# nrf54lm20a_enga_application register map
Vendor: Nordic Semiconductor; Series: nrf54l; File version: 1
CPU: CM33 r0p4, little endian, MPU, FPU, 3 interrupt priority bits, 270 interrupts, 4 SAU regions
Registers are 32-bit, read-write, reset 0x0 unless marked. A register's access mark holds for its fields unless they carry their own. Offsets are from the block's base; [hi:lo] are bit positions; {n}, {i} and the like mark numbered series; 'fields as' and 'values as' point back to an identical list.

## ETM_NS — Embedded Trace Macrocell
Base 0xE0041000
0x04 TRCPRGCTLR — Enables the trace unit.
  [0] EN — Trace unit enable bit
    0=Disabled (The trace unit is disabled. All trace resources are inactive and no trace is generated.); 1=Enabled (The trace unit is enabled.)
0x08 TRCPROCSELR — Controls which PE to trace. Might ignore writes when the trace unit is enabled or not idle. Before writing to this register, ensure that TRCSTATR.IDLE == 1 so that the trace unit can synchronize with the chosen PE. Implemented if TRCIDR3.NUMPROC is greater than zero.
  [4:0] PROCSEL — PE select bits that select the PE to trace.
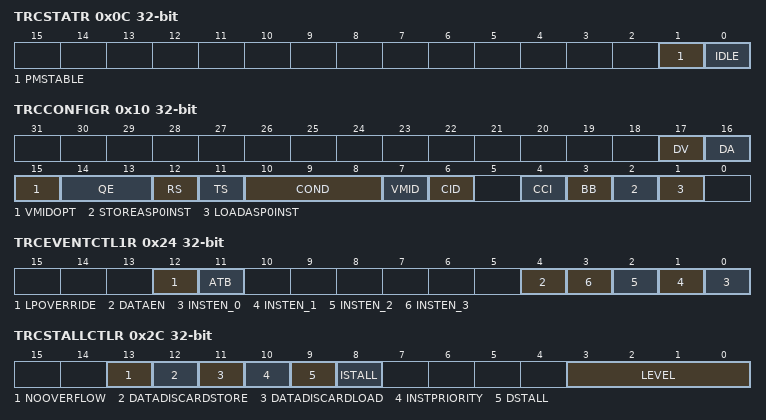
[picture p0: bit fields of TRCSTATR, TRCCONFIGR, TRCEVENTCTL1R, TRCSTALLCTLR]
0x0C TRCSTATR — Idle status bit
  [1] PMSTABLE — Programmers' model stable bit
    0=NotStable (The programmers' model is not stable.); 1=Stable (The programmers' model is stable.)
  [0] IDLE — Trace unit enable bit
    0=NotIdle (The trace unit is not idle.); 1=Idle (The trace unit is idle.)
0x10 TRCCONFIGR — Controls the tracing options This register must always be programmed as part of trace unit initialization. Might ignore writes when the trace unit is enabled or not idle.
  [17] DV — Data value tracing bit.
    0=Disabled (Data value tracing is disabled.); 1=Enabled (Data value tracing is enabled.)
  [16] DA — Data address tracing bit.
    0=Disabled (Data address tracing is disabled.); 1=Enabled (Data address tracing is enabled.)
  [15] VMIDOPT — Control bit to select the Virtual context identifier value used by the trace unit, both for trace generation and in the Virtual context identifier comparators.
    0=VTTBR_EL2 (VTTBR_EL2.VMID is used. If the trace unit supports a Virtual context identifier larger than the VTTBR_EL2.VMID, the upper unused bits are always zero. If the trace unit supports a Virtual context identifier larger than 8 bits and if the VTCR_EL2.VS bit forces use of an 8-bit Virtual context identifier, bits [15:8] of the trace unit Virtual context identifier are always zero.); 1=CONTEXTIDR_EL2 (CONTEXTIDR_EL2 is used.)
  [14:13] QE — Q element enable field.
    0=Disabled (Q elements are disabled.); 1=OnlyWithoutInstCounts (Q elements with instruction counts are enabled. Q elements without instruction counts are disabled.); 3=Enabled (Q elements with and without instruction counts are enabled.)
  [12] RS — Return stack enable bit.
    0=Disabled (Return stack is disabled.); 1=Enabled (Return stack is enabled.)
  [11] TS — Global timestamp tracing bit.
    0=Disabled (Global timestamp tracing is disabled.); 1=Enabled (Global timestamp tracing is enabled.)
  [10:8] COND — Conditional instruction tracing bit.
    0=Disabled (Conditional instruction tracing is disabled.); 1=LoadOnly (Conditional load instructions are traced.); 2=StoreOnly (Conditional store instructions are traced.); 3=LoadAndStore (Conditional load and store instructions are traced.); 7=All (All conditional instructions are traced.)
  [7] VMID — Virtual context identifier tracing bit.
    0=Disabled (Virtual context identifier tracing is disabled.); 1=Enabled (Virtual context identifier tracing is enabled.)
  [6] CID — Context ID tracing bit.
    0=Disabled (Context ID tracing is disabled.); 1=Enabled (Context ID tracing is enabled.)
  [4] CCI — Cycle counting instruction trace bit.
    0=Disabled (Cycle counting in the instruction trace is disabled.); 1=Enabled (Cycle counting in the instruction trace is enabled.)
  [3] BB — Branch broadcast mode bit.
    0=Disabled (Branch broadcast mode is disabled.); 1=Enabled (Branch broadcast mode is enabled.)
  [2] STOREASP0INST — Instruction P0 field. This field controls whether store instructions are traced as P0 instructions.
    0=No (Do not trace store instructions as P0 instructions.); 1=Yes (Trace store instructions as P0 instructions.)
  [1] LOADASP0INST — Instruction P0 load field. This field controls whether load instructions are traced as P0 instructions.
    0=No (Do not trace load instructions as P0 instructions.); 1=Yes (Trace load instructions as P0 instructions.)
0x20 TRCEVENTCTL0R — Controls the tracing of arbitrary events. If the selected event occurs a trace element is generated in the trace stream according to the settings in TRCEVENTCTL1R.DATAEN and TRCEVENTCTL1R.INSTEN.
  [7:0] EVENT — Select which event should generate trace elements.
0x24 TRCEVENTCTL1R — Controls the behavior of the events that TRCEVENTCTL0R selects. This register must always be programmed as part of trace unit initialization. Might ignore writes when the trace unit is enabled or not idle.
  [12] LPOVERRIDE — Low-power state behavior override bit. Controls how a trace unit behaves in low-power state.
    0=Disabled (Trace unit low-power state behavior is not affected. That is, the trace unit is enabled to enter low-power state.); 1=Enabled (Trace unit low-power state behavior is overridden. That is, entry to a low-power state does not affect the trace unit resources or trace generation.)
  [11] ATB — AMBA Trace Bus (ATB) trigger enable bit.
    0=Disabled (ATB trigger is disabled.); 1=Enabled (ATB trigger is enabled. If a CoreSight ATB interface is implemented then when event 0 occurs the trace unit generates an ATB event.)
  [4] DATAEN — Data event enable bit.
    0=Disabled (The trace unit does not generate an Event element if event 0 occurs.); 1=Enabled (The trace unit generates an Event element in the data trace stream if event 0 occurs.)
  [n] INSTEN_{n} (n=0..3) — Instruction event enable field.
    0=Disabled (The trace unit does not generate an Event element.); 1=Enabled (The trace unit generates an Event element for event {n}, in the instruction trace stream.)
0x2C TRCSTALLCTLR — Enables trace unit functionality that prevents trace unit buffer overflows. Might ignore writes when the trace unit is enabled or not idle. Must be programmed if TRCIDR3.STALLCTL == 1.
  [13] NOOVERFLOW — Trace overflow prevention bit.
    0=Disabled (Trace overflow prevention is disabled.); 1=Enabled (Trace overflow prevention is enabled. This might cause a significant performance impact.)
  [12] DATADISCARDSTORE — Data discard field. Controls if a trace unit can discard data trace elements on a store when the data trace buffer space is less than LEVEL.
    0=Disabled (The trace unit must not discard any data trace elements.); 1=Enabled (The trace unit can discard P1 and P2 elements associated with data stores.)
  [11] DATADISCARDLOAD — Data discard field. Controls if a trace unit can discard data trace elements on a load when the data trace buffer space is less than LEVEL.
    0=Disabled (The trace unit must not discard any data trace elements.); 1=Enabled (The trace unit can discard P1 and P2 elements associated with data loads.)
  [10] INSTPRIORITY — Prioritize instruction trace bit. Controls if a trace unit can prioritize instruction trace when the instruction trace buffer space is less than LEVEL.
    0=Disabled (The trace unit must not prioritize instruction trace.); 1=Enabled (The trace unit can prioritize instruction trace. A trace unit might prioritize instruction trace by preventing output of data trace, or other means which ensure that the instruction trace has a higher priority than the data trace.)
  [9] DSTALL — Data stall bit. Controls if a trace unit can stall the PE when the data trace buffer space is less than LEVEL.
    0=Disabled (The trace unit must not stall the PE.); 1=Enabled (The trace unit can stall the PE.)
  [8] ISTALL — Instruction stall bit. Controls if a trace unit can stall the PE when the instruction trace buffer space is less than LEVEL.
    values as DSTALL
  [3:0] LEVEL — Threshold level field. If LEVEL is nonzero then a trace unit might suppress the generation of: Global timestamps in the instruction trace stream and the data trace stream. Cycle counting in the instruction trace stream, although the cumulative cycle count remains correct.
    0=Min (Zero invasion. This setting has a greater risk of a FIFO overflow); 15=Max (Maximum invasion occurs but there is less risk of a FIFO overflow.)
0x30 TRCTSCTLR — Controls the insertion of global timestamps in the trace streams. When the selected event is triggered, the trace unit inserts a global timestamp into the trace streams. Might ignore writes when the trace unit is enabled or not idle. Must be programmed if TRCCONFIGR.TS == 1.
  [7:0] EVENT — Select which event should generate time stamps.
0x34 TRCSYNCPR — Controls how often trace synchronization requests occur. Might ignore writes when the trace unit is enabled or not idle. If writes are permitted then the register must be programmed.
  [4:0] PERIOD — Controls how many bytes of trace, the sum of instruction and data, that a trace unit can generate before a trace synchronization request occurs. The number of bytes is always a power of two, calculated by 2^PERIOD
    0=Disabled (Trace synchronization requests are disabled. This setting does not disable other types of trace synchronization request.)
0x38 TRCCCCTLR — Sets the threshold value for cycle counting. Might ignore writes when the trace unit is enabled or not idle. Must be programmed if TRCCONFIGR.CCI==1.
  [11:0] THRESHOLD — Sets the threshold value for instruction trace cycle counting.
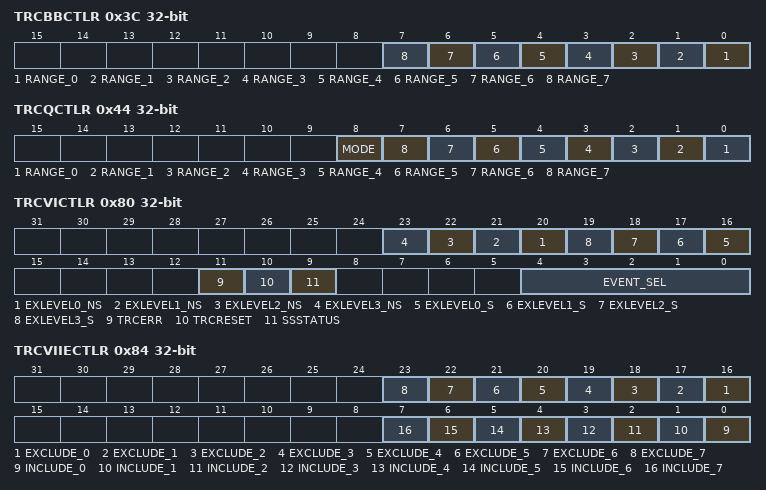
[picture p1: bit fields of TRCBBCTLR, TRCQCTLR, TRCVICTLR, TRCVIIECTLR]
0x3C TRCBBCTLR — Controls which regions in the memory map are enabled to use branch broadcasting. Might ignore writes when the trace unit is enabled or not idle. Must be programmed if TRCCONFIGR.BB == 1.
  [n] RANGE_{n} (n=0..7) — Address range field. Selects which address range comparator pairs are in use with branch broadcasting. Each field represents an address range comparator pair, so field[{n}] controls the selection of address range comparator pair {n}.
    0=Disabled (The address range that address range comparator pair {n} defines, is not selected.); 1=Enabled (The address range that address range comparator pair n defines, is selected.)
0x40 TRCTRACEIDR — Sets the trace ID for instruction trace. If data trace is enabled then it also sets the trace ID for data trace, to (trace ID for instruction trace) + 1. This register must always be programmed as part of trace unit initialization. Might ignore writes when the trace unit is enabled or not idle.
  [6:0] TRACEID — Trace ID field. Sets the trace ID value for instruction trace. Bit[0] must be zero if data trace is enabled. If data trace is enabled then a trace unit sets the trace ID for data trace, to TRACEID+1.
0x44 TRCQCTLR — Controls when Q elements are enabled. Might ignore writes when the trace unit is enabled or not idle. This register must be programmed if it is implemented and TRCCONFIGR.QE is set to any value other than 0b00.
  [8] MODE — Selects whether the address range comparators selected by the RANGE field indicate address ranges where the trace unit is permitted to generate Q elements or address ranges where the trace unit is not permitted to generate Q elements:
    0=Exclude mode. The address range comparators selected by the RANGE field indicate address ranges where the trace unit cannot generate Q elements. If no ranges are selected, Q elements are permitted across the entire memory map.; 1=Include mode. The address range comparators selected by the RANGE field indicate address ranges where the trace unit can generate Q elements. If all the implemented bits in RANGE are set to 0 then Q elements are disabled.
  [n] RANGE_{n} (n=0..7) — Specifies the address range comparators to be used for controlling Q elements.
    0=Disabled (Address range comparator {n} is disabled.); 1=Enabled (Address range comparator {n} is selected for use.)
0x80 TRCVICTLR — Controls instruction trace filtering. Might ignore writes when the trace unit is enabled or not idle. Only returns stable data when TRCSTATR.PMSTABLE == 1. Must be programmed, particularly to set the value of the SSSTATUS bit, which sets the state of the start/stop logic.
  [n+20] EXLEVEL{n}_NS (n=0..3) — In Non-secure state, each bit controls whether instruction tracing is enabled for the corresponding Exception level {n}.
    1=Disabled (The trace unit does not generate instruction trace, in Non-secure state, for Exception level {n}.); 0=Enabled (The trace unit generates instruction trace, in Non-secure state, for Exception level {n}.)
  [n+16] EXLEVEL{n}_S (n=0..3) — In Secure state, each bit controls whether instruction tracing is enabled for the corresponding Exception level {n}.
    1=Disabled (The trace unit does not generate instruction trace, in Secure state, for Exception level {n}.); 0=Enabled (The trace unit generates instruction trace, in Secure state, for Exception level {n}.)
  [11] TRCERR — When TRCIDR3.TRCERR==1, this bit controls whether a trace unit must trace a System error exception.
    0=Disabled (The trace unit does not trace a System error exception unless it traces the exception or instruction immediately prior to the System error exception.); 1=Enabled (The trace unit always traces a System error exception, regardless of the value of ViewInst.)
  [10] TRCRESET — Controls whether a trace unit must trace a Reset exception.
    0=Disabled (The trace unit does not trace a Reset exception unless it traces the exception or instruction immediately prior to the Reset exception.); 1=Enabled (The trace unit always traces a Reset exception.)
  [9] SSSTATUS — When TRCIDR4.NUMACPAIRS > 0 or TRCIDR4.NUMPC > 0, this bit returns the status of the start/stop logic.
    0=Stopped (The start/stop logic is in the stopped state.); 1=Started (The start/stop logic is in the started state.)
  [4:0] EVENT_SEL — Select which resource number should be filtered.
    0=Disabled (This event is not filtered.); 1=Enabled (This event is filtered.)
0x84 TRCVIIECTLR — ViewInst exclude control. Might ignore writes when the trace unit is enabled or not idle. This register must be programmed when one or more address comparators are implemented.
  [n+16] EXCLUDE_{n} (n=0..7) — Exclude range field. Selects which address range comparator pairs are in use with ViewInst exclude control.
    0=Disabled (The address range that address range comparator pair {n} defines, is not selected for ViewInst exclude control.); 1=Enabled (The address range that address range comparator pair {n} defines, is selected for ViewInst exclude control.)
  [n] INCLUDE_{n} (n=0..7) — Include range field. Selects which address range comparator pairs are in use with ViewInst include control.
    0=Disabled (The address range that address range comparator pair {n} defines, is not selected for ViewInst include control.); 1=Enabled (The address range that address range comparator pair {n} defines, is selected for ViewInst include control.)
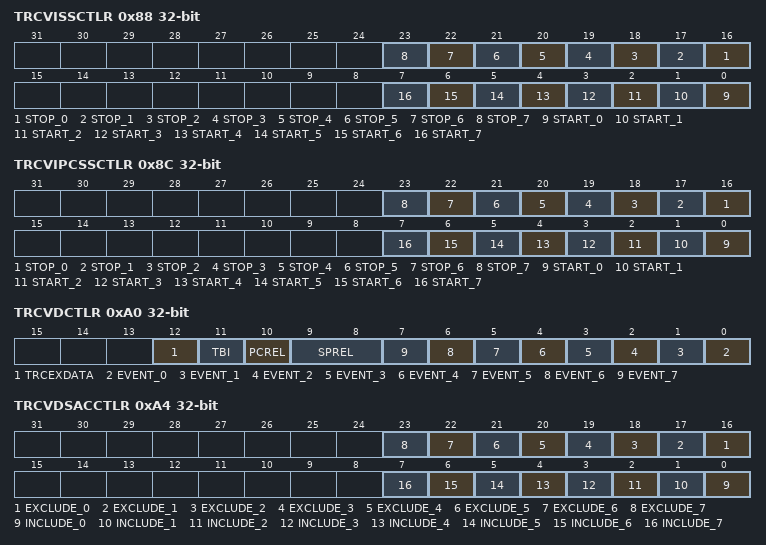
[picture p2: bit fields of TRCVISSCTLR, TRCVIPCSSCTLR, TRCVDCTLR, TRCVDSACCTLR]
0x88 TRCVISSCTLR — Use this to set, or read, the single address comparators that control the ViewInst start/stop logic. The start/stop logic is active for an instruction which causes a start and remains active up to and including an instruction which causes a stop, and then the start/stop logic becomes inactive. Might ignore writes when the trace unit is enabled or not idle. If implemented then this register must be programmed.
  [n+16] STOP_{n} (n=0..7) — Selects which single address comparators are in use with ViewInst start/stop control, for the purpose of stopping trace
    0=Disabled (The single address comparator {n}, is not selected as a stop resource.); 1=Enabled (The single address comparator {n}, is selected as a stop resource.)
  [n] START_{n} (n=0..7) — Selects which single address comparators are in use with ViewInst start/stop control, for the purpose of starting trace.
    0=Disabled (The single address comparator {n}, is not selected as a start resource.); 1=Enabled (The single address comparator {n}, is selected as a start resource.)
0x8C TRCVIPCSSCTLR — Use this to set, or read, which PE comparator inputs can control the ViewInst start/stop logic. Might ignore writes when the trace unit is enabled or not idle. If implemented then this register must be programmed.
  [n+16] STOP_{n} (n=0..7) — Selects which PE comparator inputs are in use with ViewInst start/stop control, for the purpose of stopping trace.
    0=Disabled (The single PE comparator input {n}, is not selected as a stop resource.); 1=Enabled (The single PE comparator input {n}, is selected as a stop resource.)
  [n] START_{n} (n=0..7) — Selects which PE comparator inputs are in use with ViewInst start/stop control, for the purpose of starting trace
    0=Disabled (The single PE comparator input {n}, is not selected as a start resource.); 1=Enabled (The single PE comparator input {n}, is selected as a start resource.)
0xA0 TRCVDCTLR — Controls data trace filtering. Might ignore writes when the trace unit is enabled or not idle. This register must be programmed when data tracing is enabled, that is, when either TRCCONFIGR.DA == 1 or TRCCONFIGR.DV == 1.
  [12] TRCEXDATA — Controls the tracing of data transfers for exceptions and exception returns on Armv6-M, Armv7-M, and Armv8-M PEs.
    0=Disabled (Exception and exception return data transfers are not traced.); 1=Enabled (Exception and exception return data transfers are traced if the other aspects of ViewData indicate that the data transfers must be traced.)
  [11] TBI — Controls which information a trace unit populates in bits[63:56] of the data address.
    0=SignExtend (The trace unit assigns bits[63:56] to have the same value as bit[55] of the data address, that is, it sign-extends the value.); 1=Copy (The trace unit assigns bits[63:56] to have the same value as bits[63:56] of the data address.)
  [10] PCREL — Controls whether a trace unit traces data for transfers that are relative to the Program Counter (PC).
    0=Enabled (The trace unit does not affect the tracing of PC-relative transfers.); 1=Disabled (The trace unit does not trace the address or value portions of PC-relative transfers.)
  [9:8] SPREL — Controls whether a trace unit traces data for transfers that are relative to the Stack Pointer (SP).
    0=Enabled (The trace unit does not affect the tracing of SP-relative transfers.); 2=DataOnly (The trace unit does not trace the address portion of SP-relative transfers. If data value tracing is enabled then the trace unit generates a P1 data address element.); 3=Disabled (The trace unit does not trace the address or value portions of SP-relative transfers.)
  [n] EVENT_{n} (n=0..7) — Event unit enable bit.
    0=Disabled (The trace event is not selected for trace filtering.); 1=Enabled (The trace event is selected for trace filtering.)
0xA4 TRCVDSACCTLR — ViewData include / exclude control. Might ignore writes when the trace unit is enabled or not idle. This register must be programmed when one or more address comparators are implemented.
  [n+16] EXCLUDE_{n} (n=0..7) — Selects which single address comparators are in use with ViewData exclude control.
    0=Disabled (The single address comparator {n}, is not selected for ViewData exclude control.); 1=Enabled (The single address comparator {n}, s selected for ViewData exclude control.)
  [n] INCLUDE_{n} (n=0..7) — Selects which single address comparators are in use with ViewData include control.
    0=Disabled (The single address comparator {n}, is not selected for ViewData include control.); 1=Enabled (The single address comparator {n}, is selected for ViewData include control.)
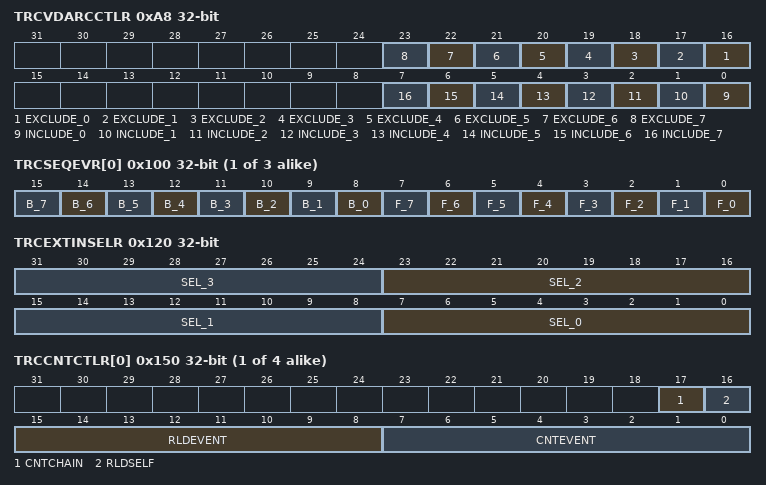
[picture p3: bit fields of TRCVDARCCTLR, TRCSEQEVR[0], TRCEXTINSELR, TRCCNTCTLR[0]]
0xA8 TRCVDARCCTLR — ViewData include / exclude control. Might ignore writes when the trace unit is enabled or not idle. This register must be programmed when one or more address comparators are implemented.
  [n+16] EXCLUDE_{n} (n=0..7) — Exclude range field. Selects which address range comparator pairs are in use with ViewData exclude control.
    0=Disabled (The address range that address range comparator {n} defines, is not selected for ViewData exclude control.); 1=Enabled (The address range that address range comparator {n} defines, s selected for ViewData exclude control.)
  [n] INCLUDE_{n} (n=0..7) — Include range field. Selects which address range comparator pairs are in use with ViewData include control.
    0=Disabled (The address range that address range comparator {n} defines, is not selected for ViewData include control.); 1=Enabled (The address range that address range comparator {n} defines, is selected for ViewData include control.)
{0x100+4i} TRCSEQEVR[{i}] (i=0..2) — Description collection: Moves the sequencer state according to programmed events. Might ignore writes when the trace unit is enabled or not idle. When the sequencer is used, all sequencer state transitions must be programmed with a valid event.
  [n+8] B_{n} (n=0..7) — Backward field.
    0=Disabled (The trace event does not affect the sequencer.); 1=Enabled (When the event occurs then the sequencer state moves from state n+1 to state n.)
  [n] F_{n} (n=0..7) — Forward field.
    0=Disabled (The trace event does not affect the sequencer.); 1=Enabled (When the event occurs then the sequencer state moves from state n to state n+1.)
0x118 TRCSEQRSTEVR — Moves the sequencer to state 0 when a programmed event occurs. Might ignore writes when the trace unit is enabled or not idle. When the sequencer is used, all sequencer state transitions must be programmed with a valid event.
  [7:0] EVENT — Select which event should reset the sequencer.
0x11C TRCSEQSTR — Use this to set, or read, the sequencer state. Might ignore writes when the trace unit is enabled or not idle. Only returns stable data when TRCSTATR.PMSTABLE == 1. When the sequencer is used, all sequencer state transitions must be programmed with a valid event.
  [1:0] STATE — Sets or returns the state of the sequencer.
    {v}=The sequencer is in state {v} (v=0..3)
0x120 TRCEXTINSELR — Use this to set, or read, which external inputs are resources to the trace unit. Might ignore writes when the trace unit is enabled or not idle. Only returns stable data when TRCSTATR.PMSTABLE == 1. When the sequencer is used, all sequencer state transitions must be programmed with a valid event.
  [8n+7:8n] SEL_{n} (n=0..3) — Each field in this collection selects an external input as a resource for the trace unit.
{0x140+4i} TRCCNTRLDVR[{i}] (i=0..3) — Description collection: This sets or returns the reload count value for counter n. Might ignore writes when the trace unit is enabled or not idle.
  [15:0] VALUE — Contains the reload value for counter n. When a reload event occurs for counter n then the trace unit copies the VALUEn field into counter n.
{0x150+4i} TRCCNTCTLR[{i}] (i=0..3) — Description collection: Controls the operation of counter n. Might ignore writes when the trace unit is enabled or not idle.
  [17] CNTCHAIN — For TRCCNTCTLR3 and TRCCNTCTLR1, this bit controls whether counter n decrements when a reload event occurs for counter n-1.
    0=Disabled (Counter n does not decrement when a reload event for counter n-1 occurs.); 1=Enabled (Counter n decrements when a reload event for counter n-1 occurs. This concatenates counter n and counter n-1, to provide a larger count value.)
  [16] RLDSELF — Controls whether a reload event occurs for counter n, when counter n reaches zero.
    0=Disabled (The counter is in Normal mode.); 1=Enabled (The counter is in Self-reload mode.)
  [15:8] RLDEVENT — Selects an event, that when it occurs causes a reload event for counter n.
  [7:0] CNTEVENT — Selects an event, that when it occurs causes counter n to decrement.
{0x160+4i} TRCCNTVR[{i}] (i=0..3) — Description collection: This sets or returns the value of counter n. The count value is only stable when TRCSTATR.PMSTABLE == 1. If software uses counter n then it must write to this register to set the initial counter value. Might ignore writes when the trace unit is enabled or not idle.
  [15:0] VALUE — Contains the count value of counter n.
{0x200+4i} TRCRSCTLR[{i}] (i=0..29) — Description collection: Controls the selection of the resources in the trace unit. Might ignore writes when the trace unit is enabled or not idle. If software selects a non-implemented resource then CONSTRAINED UNPREDICTABLE behavior of the resource selector occurs, so the resource selector might fire unexpectedly or might not fire. Reads of the TRCRSCTLRn might return UNKNOWN.
  fields as TRCPRGCTLR
0x280 TRCSSCCR0 — Controls the single-shot comparator.
  [24] RST — Enables the single-shot comparator resource to be reset when it occurs, to enable another comparator match to be detected
    0=Disabled (Multiple matches can not be detected.); 1=Enabled (Multiple matches can occur.)
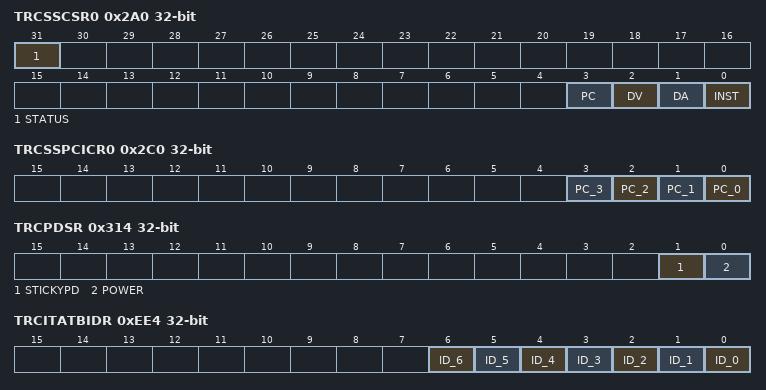
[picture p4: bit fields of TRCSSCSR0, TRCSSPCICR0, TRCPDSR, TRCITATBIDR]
0x2A0 TRCSSCSR0 — Indicates the status of the single-shot comparators. TRCSSCSR0 is sensitive toinstruction addresses.
  [31] STATUS — Single-shot status. This indicates whether any of the selected comparators have matched.
    0=NoMatch (Match has not occurred.); 1=Match has occurred at least once
  [3] PC — Process counter value comparator support
    0=False (Process counter value comparisons not supported.); 1=True (Process counter value comparisons supported.)
  [2] DV — Data value comparator support
    0=False (Data value comparisons not supported.); 1=True (Data value comparisons supported.)
  [1] DA — Data address comparator support
    0=False (Data address comparisons not supported.); 1=True (Data address comparisons supported.)
  [0] INST — Instruction address comparator support
    0=False (Single-shot instruction address comparisons not supported.); 1=True (Single-shot instruction address comparisons supported.)
0x2C0 TRCSSPCICR0 — Selects the processor comparator inputs for Single-shot control.
  [n] PC_{n} (n=0..3) — Selects processor comparator {n} inputs for Single-shot control
    0=Disabled (Processor comparator {n} is not selected for Single-shot control.); 1=Enabled (Processor comparator {n} is selected for Single-shot control.)
0x310 TRCPDCR — Controls the single-shot comparator.
  [24] PU — Power up request, to request that power to ETM and access to the trace registers is maintained.
    0=Disabled (Power not requested.); 1=Enabled (Power requested.)
0x314 TRCPDSR — Indicates the power down status of the ETM.
  [1] STICKYPD — Sticky power down state. This bit is set to 1 when power to the ETM registers is removed, to indicate that programming state has been lost. It is cleared after a read of the TRCPDSR
    0=NotPoweredDown (Trace register power has not been removed since the TRCPDSR was last read.); 1=PoweredDown (Trace register power has been removed since the TRCPDSR was last read.)
  [0] POWER — Indicates ETM is powered up
    0=NotPoweredUp (ETM is not powered up. All registers are not accessible.); 1=PoweredUp (ETM is powered up. All registers are accessible.)
0xEE4 TRCITATBIDR — Sets the state of output pins.
  [n] ID_{n} (n=0..6) — Drives the ATIDMI[{n}] output pin.
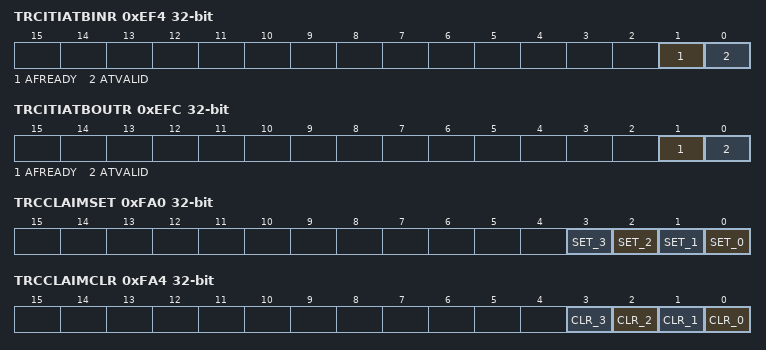
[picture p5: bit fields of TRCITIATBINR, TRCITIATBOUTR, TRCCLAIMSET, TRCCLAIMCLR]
0xEF4 TRCITIATBINR — Reads the state of the input pins.
  [1] AFREADY — Returns the value of the AFREADYMI input pin.
  [0] ATVALID — Returns the value of the ATVALIDMI input pin.
0xEFC TRCITIATBOUTR — Sets the state of the output pins.
  [1] AFREADY — Drives the AFREADYMI output pin.
  [0] ATVALID — Drives the ATVALIDMI output pin.
0xF00 TRCITCTRL — Enables topology detection or integration testing, by putting ETM-M33 into integration mode.
  [0] IME — Integration mode enable
    0=Disabled (ETM is not in integration mode.); 1=Enabled (ETM is in integration mode.)
0xFA0 TRCCLAIMSET — Sets bits in the claim tag and determines the number of claim tag bits implemented.
  [n] SET_{n} (n=0..3) — Claim tag set register
    on read: 0=NotSet (Claim tag {n} is not set.); 1=Set (Claim tag {n} is set.) | on write: 1=Claim (Set claim tag {n}.)
0xFA4 TRCCLAIMCLR — Clears bits in the claim tag and determines the current value of the claim tag.
  [n] CLR_{n} (n=0..3) — Claim tag clear register
    on read: 0=NotSet (Claim tag {n} is not set.); 1=Set (Claim tag {n} is set.) | on write: 1=Clear claim tag {n}
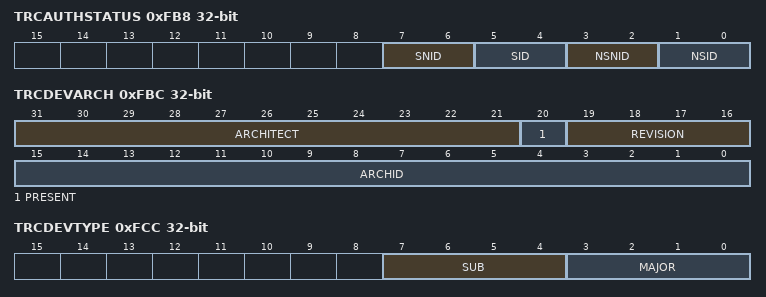
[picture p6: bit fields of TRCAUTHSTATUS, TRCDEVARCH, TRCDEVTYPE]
0xFB8 TRCAUTHSTATUS — Indicates the current level of tracing permitted by the system
  [all] fields
    0=NotImplemented (The feature is not implemented.); 1=Implemented (The feature is implemented.)
  [7:6] SNID — Secure Non-Invasive Debug
  [5:4] SID — Secure Invasive Debug
  [3:2] NSNID — Non-secure Non-Invasive Debug
  [1:0] NSID — Non-secure Invasive Debug
0xFBC TRCDEVARCH ro — The TRCDEVARCH identifies ETM-M33 as an ETMv4.2 component
  [31:21] ARCHITECT — Defines the architect of the component
    0x23B=Arm (This peripheral was architected by Arm.)
  [20] PRESENT — This register is implemented
    0=Absent (The register is not implemented.); 1=Present (The register is implemented.)
  [19:16] REVISION — Architecture revision
    2=v2 (Component is part of architecture 4.2)
  [15:0] ARCHID — Architecture ID
    0x4A13=ETMv42 (Component is an ETMv4 component)
0xFCC TRCDEVTYPE ro — Controls the single-shot comparator.
  [7:4] SUB — The sub-type of the component
    1=ProcessorTrace (Peripheral is a processor trace source.)
  [3:0] MAJOR — The main type of the component
    3=TraceSource (Peripheral is a trace source.)
{0xFD0+4i} TRCPIDR[{i}] (i=0..7) — Description collection: Coresight peripheral identification registers.
{0xFF0+4i} TRCCIDR[{i}] (i=0..3) — Description collection: Coresight component identification registers.
